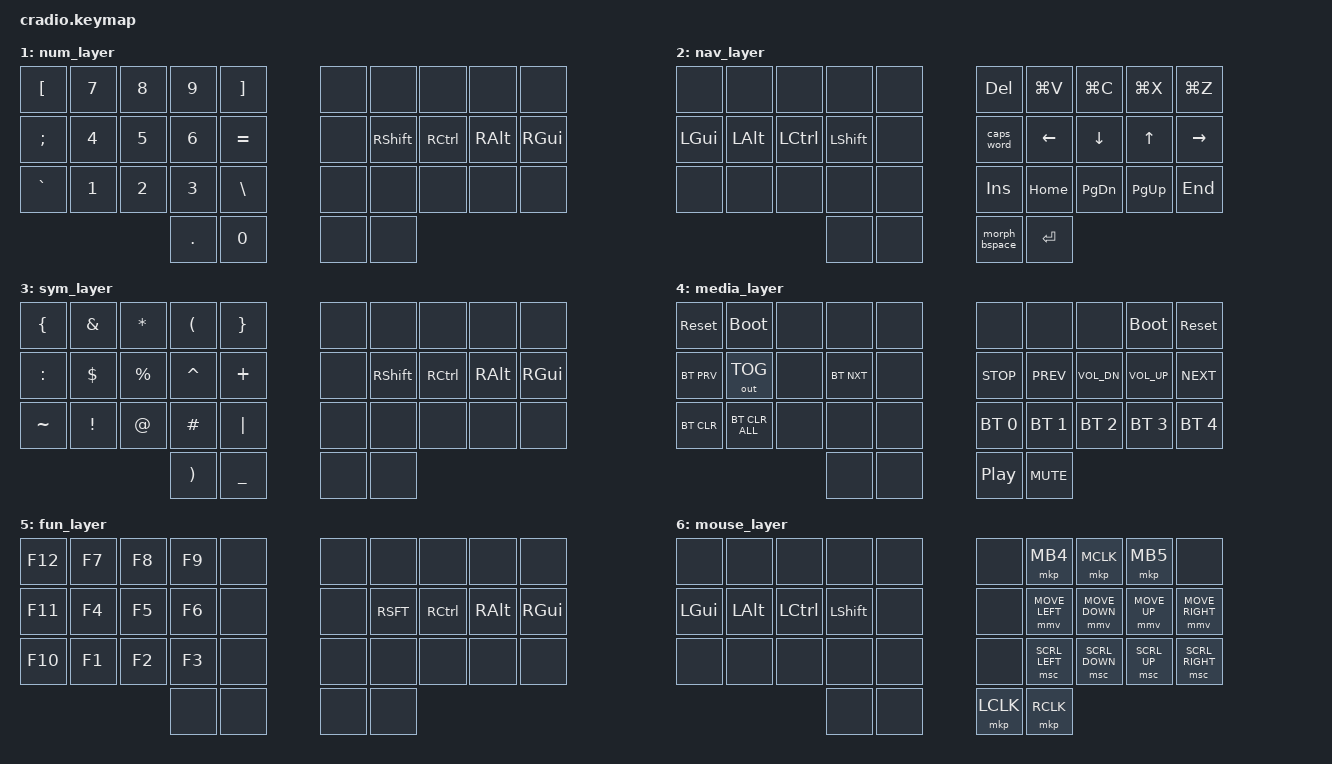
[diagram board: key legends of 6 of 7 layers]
// Copyright (c) 2022 The ZMK Contributors
// SPDX-License-Identifier: MIT

#include <behaviors.dtsi>
#include <dt-bindings/zmk/keys.h>
#include <dt-bindings/zmk/bt.h>
#include <dt-bindings/zmk/outputs.h>


#define ZMK_POINTING_DEFAULT_MOVE_VAL 1500  // default: 600
#define ZMK_POINTING_DEFAULT_SCRL_VAL 20    // default: 10

#include <dt-bindings/zmk/pointing.h>

// Home row mods macro
#define HRML(k1,k2,k3,k4) &ht LGUI k1 &ht LALT k2  &ht LCTRL k3  &ht LSHFT k4
#define HRMR(k1,k2,k3,k4) &ht RSHFT k1  &ht RCTRL k2  &ht RALT k3  &ht RGUI k4


// Layer aliases
#define DEF 0
#define NUM 1
#define NAV 2
#define SYM 3
#define MED 4
#define FUN 5
#define MOU 6

/ {
    behaviors {
        ht: hold_tap {
            compatible = "zmk,behavior-hold-tap";
            #binding-cells = <2>;
            flavor = "tap-preferred";
            tapping-term-ms = <220>;
            quick-tap-ms = <150>;
            require-prior-idle-ms = <100>;
            bindings = <&kp>, <&kp>;
        };

        morph_comma: comma_to_semicolon {
            compatible = "zmk,behavior-mod-morph";
            #binding-cells = <0>;
            bindings = <&kp COMMA>, <&kp SEMI>;
            mods = <(MOD_LSFT|MOD_RSFT)>;
        };

        morph_hash: hash_to_at {
            compatible = "zmk,behavior-mod-morph";
            #binding-cells = <0>;
            bindings = <&kp HASH>, <&kp AT>;
            mods = <(MOD_LSFT|MOD_RSFT)>;
        };

        morph_dash: dash_to_plus {
            compatible = "zmk,behavior-mod-morph";
            #binding-cells = <0>;
            bindings = <&kp MINUS>, <&kp PLUS>;
            mods = <(MOD_LSFT|MOD_RSFT)>;
        };

        morph_dot: dot_to_colon {
            compatible = "zmk,behavior-mod-morph";
            #binding-cells = <0>;
            bindings = <&kp DOT>, <&kp COLON>;
            mods = <(MOD_LSFT|MOD_RSFT)>;
        };

        morph_sqt: sqoute_to_qmark {
            compatible = "zmk,behavior-mod-morph";
            #binding-cells = <0>;
            bindings = <&kp SQT>, <&kp QMARK>;
            mods = <(MOD_LSFT|MOD_RSFT)>;
        };

        morph_dqt: dqt_to_excl {
            compatible = "zmk,behavior-mod-morph";
            #binding-cells = <0>;
            bindings = <&kp DQT>, <&kp EXCL>;
            mods = <(MOD_LSFT|MOD_RSFT)>;
        };

        morph_fslash: fslash_to_asterisk {
            compatible = "zmk,behavior-mod-morph";
            #binding-cells = <0>;
            bindings = <&kp FSLH>, <&kp ASTERISK>;
            mods = <(MOD_LSFT|MOD_RSFT)>;
        };

        morph_bspace: backspace_delete {
            compatible = "zmk,behavior-mod-morph";
            #binding-cells = <0>;
            bindings = <&kp BACKSPACE>, <&kp DELETE>;
            mods = <(MOD_LSFT)>;
        };
    };

    combos {
        compatible = "zmk,combos";
        combo_z {
            timeout-ms = <50>;
            key-positions = <0 1>;
            bindings = <&kp Z>;
        };

        combo_q {
            timeout-ms = <50>;
            key-positions = <1 3>;
            bindings = <&kp Q>;
        };

        fun_layer {
            timeout-ms = <50>;
            key-positions = <31 33>;
            bindings = <&tog FUN>;
        };

        mouse_layer {
            timeout-ms = <50>;
            key-positions = <31 32>;
            bindings = <&tog MOU>;
        };

        nav_layer {
            timeout-ms = <50>;
            key-positions = <30 33>;
            bindings = <&tog NAV>;
        };
    };

    keymap {
        compatible = "zmk,keymap";
        default_layer {
            bindings = <
        //╭──────────┬──────────┬──────────┬──────────┬──────────╮   ╭──────────┬──────────┬──────────┬──────────┬──────────╮
        //│  X       │  W       │  M       │  G       │  " !     │   │  # @     │  . :     │  ' ?     │  J       │  B       │
            &kp X      &kp W      &kp M      &kp G      &morph_dqt    &morph_hash &morph_dot &morph_sqt     &kp J      &kp B
        //├──────────┼──────────┼──────────┼──────────┼──────────┤   ├──────────┼──────────┼──────────┼──────────┼──────────┤
        //│  S       │  C       │  N       │  T       │  K       │   │  , ;       │  A       │  E       │  I       │   H      │
            HRML(S,        C,         N,         T)     &kp K         &morph_comma HRMR(A,        E,         I,        H)
        //├──────────┼──────────┼──────────┼──────────┼──────────┤   ├──────────┼──────────┼──────────┼──────────┼──────────┤
        //│  V       │  P       │  L       │  D       │  / *     │   │  - +     │  M       │    O     │ . >      │ / ?      │
            &kp V      &kp P      &kp L      &kp D      &morph_fslash &morph_dash   &kp U      &kp O      &kp Y      &kp F
        //╰──────────┴──────────┴──────────┼──────────┼──────────┤   ├──────────┼──────────┼──────────┴──────────┴──────────╯
                                           &lt NAV SPACE  &lt MED TAB     &lt SYM BSPC   &lt NUM R
        //                                 ╰──────────┴──────────╯   ╰──────────┴──────────╯
            >;
        };

        num_layer {
            bindings = <
        //╭──────────┬──────────┬──────────┬──────────┬──────────╮   ╭──────────┬──────────┬──────────┬──────────┬──────────╮
        //│    [     │  7       │  8       │  9       │    ]     │   │          │          │          │          │          │
            &kp LBKT    &kp N7     &kp N8     &kp N9    &kp RBKT        &none     &none     &none     &none     &none
        //├──────────┼──────────┼──────────┼──────────┼──────────┤   ├──────────┼──────────┼──────────┼──────────┼──────────┤
        //│     ;    │  4       │  5       │  6       │     =    │   │          │ RSFT     │ RCTRL    │   RALT   │  RGUI    │
            &kp SEMI    &kp N4     &kp N5     &kp N6    &kp EQUAL       &none    &kp RSHFT   &kp RCTRL  &kp RALT   &kp RGUI
        //├──────────┼──────────┼──────────┼──────────┼──────────┤   ├──────────┼──────────┼──────────┼──────────┼──────────┤
        //│    `     │  1       │  2       │  3       │     \    │   │          │          │          │          │          │
           &kp GRAVE   &kp N1     &kp N2       &kp N3    &kp BSLH         &none   &none     &none     &none     &none
        //╰──────────┴──────────┴──────────┼──────────┼──────────┤   ├──────────┼──────────┼──────────┴──────────┴──────────╯
                                             &kp DOT    &kp N0        &none     &none
        //                                 ╰──────────┴──────────╯   ╰──────────┴──────────╯
            >;
        };

        nav_layer {
            bindings = <
        //╭──────────┬──────────┬──────────┬──────────┬──────────╮   ╭──────────┬──────────┬──────────┬──────────┬──────────╮
        //│          │          │          │          │          │   │          │          │          │          │          │
           &none        &none     &none     &none       &none           &kp DEL  &kp LG(V)  &kp LG(C)  &kp LG(X)  &kp LG(Z)
        //├──────────┼──────────┼──────────┼──────────┼──────────┤   ├──────────┼──────────┼──────────┼──────────┼──────────┤
        //│          │          │          │          │          │   |          │          │          │          |          |
            &kp LGUI   &kp LALT   &kp LCTRL   &kp LSHFT   &none        &caps_word &kp LEFT   &kp DOWN    &kp UP    &kp RIGHT
        //├──────────┼──────────┼──────────┼──────────┼──────────┤   ├──────────┼──────────┼──────────┼──────────┼──────────┤
        //│          │          │          │          │          │   │          │          │          │          │          │
            &none     &none     &none       &none      &none          &kp INS     &kp HOME  &kp PG_DN   &kp PG_UP   &kp END
        //╰──────────┴──────────┴──────────┼──────────┼──────────┤   ├──────────┼──────────┼──────────┴──────────┴──────────╯
                                             &none     &none         &morph_bspace     &kp ENTER
        //                                 ╰──────────┴──────────╯   ╰──────────┴──────────╯
            >;
        };

        sym_layer {
            bindings = <
        //╭──────────┬──────────┬──────────┬──────────┬──────────╮   ╭──────────┬──────────┬──────────┬──────────┬──────────╮
        //│     {    │     &    │    *     │     (    │      }   │   │  ^       │          │          │          │         │
           &kp LBRC    &kp AMPS   &kp ASTRK   &kp LPAR   &kp RBRC            &none  &none   &none   &none   &none
        //├──────────┼──────────┼──────────┼──────────┼──────────┤   ├──────────┼──────────┼──────────┼──────────┼──────────┤
        //│  !       │  @       │  #       │  $       │  %       │   │  *       │  -       │  =       │  \       │  `       │
            &kp COLON   &kp DLLR  &kp PRCNT   &kp CARET &kp PLUS        &none     &kp RSHFT  &kp RCTRL   &kp RALT   &kp RGUI
        //├──────────┼──────────┼──────────┼──────────┼──────────┤   ├──────────┼──────────┼──────────┼──────────┼──────────┤
        //│          │          │          │          │          │   │  &       │  _       │  +       │  │       │          │
            &kp TILDE   &kp EXCL     &kp AT     &kp HASH     &kp PIPE    &none   &none  &none   &none   &none
        //╰──────────┴──────────┴──────────┼──────────┼──────────┤   ├──────────┼──────────┼──────────┴──────────┴──────────╯
                                             &kp RPAR     &kp UNDER         &none     &none
        //                                 ╰──────────┴──────────╯   ╰──────────┴──────────╯
            >;
        };

        media_layer {
            bindings = <
        //╭──────────┬──────────┬──────────┬──────────┬──────────╮   ╭──────────┬──────────┬──────────┬──────────┬──────────╮
        //│ RESET    │BOOTLOADER│          │          │          │   │          │          │          │BOOTLOADER│ RESET    │
           &sys_reset &bootloader     &none     &none     &none          &none     &none     &none     &bootloader &sys_reset
        //├──────────┼──────────┼──────────┼──────────┼──────────┤   ├──────────┼──────────┼──────────┼──────────┼──────────┤
        //| BT PREV  │          │          │BT NEXT  │          │      STOP    │PREV TRACK│ VOL DOWN │ VOL UP   │NEXT TRACK│
           &bt BT_PRV &out OUT_TOG &none     &bt BT_NXT     &none      &kp C_STOP &kp C_PREV  &kp C_VOL_DN &kp C_VOL_UP &kp C_NEXT
        //├──────────┼──────────┼──────────┼──────────┼──────────┤   ├──────────┼──────────┼──────────┼──────────┼──────────┤
        //│          │          │          │          │          │   │PROFILE 0 │PROFILE 1 │PROFILE 2 │PROFILE 3 │PROFILE 4 │
           &bt BT_CLR &bt BT_CLR_ALL     &none       &none      &none  &bt BT_SEL 0 &bt BT_SEL 1 &bt BT_SEL 2 &bt BT_SEL 3 &bt BT_SEL 4
        //╰──────────┴──────────┴──────────┼──────────┼──────────┤   ├──────────┼──────────┼──────────┴──────────┴──────────╯
                                             &none     &none            &kp C_PP &kp C_MUTE
        //                                 ╰──────────┴──────────╯   ╰──────────┴──────────╯
            >;
        };

        fun_layer {
            bindings = <
        //╭──────────┬──────────┬──────────┬──────────┬──────────╮   ╭──────────┬──────────┬──────────┬──────────┬──────────╮
        //│          │          │          │          │          │              │          │          │          │          │
           &kp F12  &kp F7     &kp F8     &kp F9          &none         &none     &none     &none     &none         &none
        //├──────────┼──────────┼──────────┼──────────┼──────────┤   ├──────────┼──────────┼──────────┼──────────┼──────────┤
        //│          │          │          │          │          │   │          │          │          │          │          │
          &kp F11       &kp F4     &kp F5     &kp F6      &none         &none     &kp RSFT  &kp RCTRL   &kp RALT   &kp RGUI
        //├──────────┼──────────┼──────────┼──────────┼──────────┤   ├──────────┼──────────┼──────────┼──────────┼──────────┤
        //│          │          │          │          │          │   │          │          │          │          │          │
            &kp F10     &kp F1     &kp F2    &kp F3      &none          &none     &none     &none     &none     &none
        //╰──────────┴──────────┴──────────┼──────────┼──────────┤   ├──────────┼──────────┼──────────┴──────────┴──────────╯
                                             &none     &none         &none     &none
        //                                 ╰──────────┴──────────╯   ╰──────────┴──────────╯
            >;
        };

        mouse_layer {
            bindings = <
        //╭──────────┬──────────┬──────────┬──────────┬──────────╮   ╭──────────┬──────────┬──────────┬──────────┬──────────╮
        //│          │          │          │          │          │   │          │          │          │          │          │
           &none        &none     &none     &none        &none          &none     &mkp MB4   &mkp MCLK   &mkp MB5   &none
        //├──────────┼──────────┼──────────┼──────────┼──────────┤   ├──────────┼──────────┼──────────┼──────────┼──────────┤
        //│          │          │          │          │          │   │          │          │          │          │          │
            &kp LGUI   &kp LALT   &kp LCTRL  &kp LSHFT   &none          &none   &mmv MOVE_LEFT &mmv MOVE_DOWN &mmv MOVE_UP &mmv MOVE_RIGHT
        //├──────────┼──────────┼──────────┼──────────┼──────────┤   ├──────────┼──────────┼──────────┼──────────┼──────────┤
        //│          │          │          │          │          │   │          │          │          │          │          │
            &none     &none     &none    &none      &none          &none     &msc SCRL_LEFT     &msc SCRL_DOWN     &msc SCRL_UP     &msc SCRL_RIGHT
        //╰──────────┴──────────┴──────────┼──────────┼──────────┤   ├──────────┼──────────┼──────────┴──────────┴──────────╯
                                             &none     &none         &mkp LCLK     &mkp RCLK
        //                                 ╰──────────┴──────────╯   ╰──────────┴──────────╯
            >;
        };

    };
    
};
